VERSION ""

NS_ :

BS_:

BU_: XXX

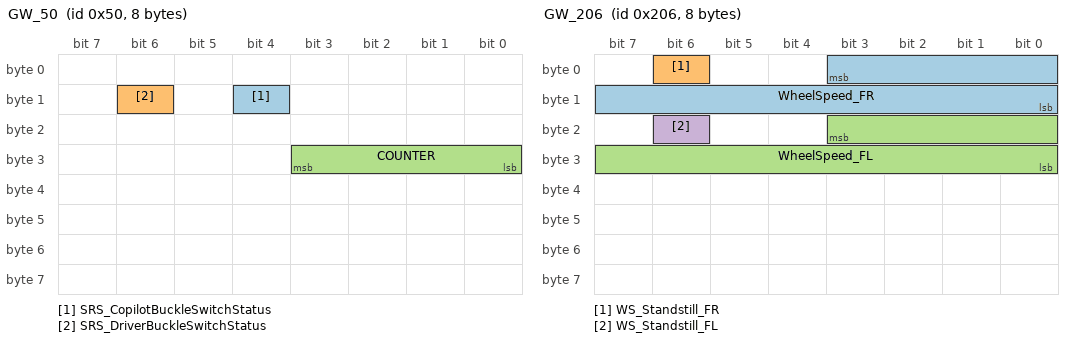
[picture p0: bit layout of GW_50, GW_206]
BO_ 80 GW_50: 8 XXX
 SG_ SRS_CopilotBuckleSwitchStatus : 12|1@0+ (1,0) [0|1] "" XXX
 SG_ SRS_DriverBuckleSwitchStatus : 14|1@0+ (1,0) [0|1] "" XXX
 SG_ COUNTER : 27|4@0+ (1,0) [0|15] "" XXX

BO_ 384 GW_180: 8 XXX
 SG_ SAS_SteeringAngle : 0|16@1- (0.1,1) [-476|476] "deg" XXX
 SG_ SAS_SteeringAngleSpeed : 16|8@0+ (1,0) [0|255] "" XXX
 SG_ COUNTER : 48|4@0+ (1,0) [0|15] "" XXX
 SG_ CHECKSUM : 63|8@0+ (1,0) [0|255] "" XXX

BO_ 391 GW_187: 8 XXX
 SG_ ESP_VehicleSpeed : 39|16@0+ (0.05,0) [0|255] "km/h" XXX
 SG_ COUNTER : 48|4@0+ (1,0) [0|15] "" XXX
 SG_ CHECKSUM : 63|8@0+ (1,0) [0|255] "" XXX

BO_ 424 GW_1A8: 8 XXX
 SG_ GearPosition : 8|4@1+ (1,0) [0|15] "" XXX
 SG_ COUNTER : 48|4@0+ (1,0) [0|15] "" XXX
 SG_ CHECKSUM : 63|8@0+ (1,0) [0|255] "" XXX

BO_ 518 GW_206: 8 XXX
 SG_ WheelSpeed_FR : 3|12@0+ (0.05,0) [0|204.75] "km/h" XXX
 SG_ WS_Standstill_FR : 6|1@0+ (1,0) [0|1] "" XXX
 SG_ WheelSpeed_FL : 19|12@0+ (0.05,0) [0|204.75] "km/h" XXX
 SG_ WS_Standstill_FL : 22|1@0+ (1,0) [0|1] "" XXX

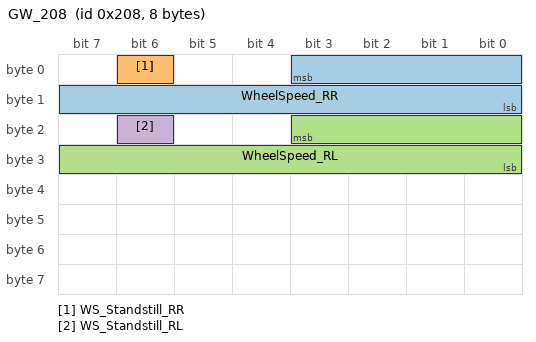
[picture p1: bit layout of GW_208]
BO_ 520 GW_208: 8 XXX
 SG_ WheelSpeed_RR : 3|12@0+ (0.05,0) [0|204.75] "km/h" XXX
 SG_ WS_Standstill_RR : 6|1@0+ (1,0) [0|1] "" XXX
 SG_ WheelSpeed_RL : 19|12@0+ (0.05,0) [0|204.75] "km/h" XXX
 SG_ WS_Standstill_RL : 22|1@0+ (1,0) [0|1] "" XXX

BO_ 618 GW_26A: 8 XXX
 SG_ EMS_AccelSwitch : 0|1@0+ (1,0) [0|1] "" XXX
 SG_ AcceleratorPedalPosition : 47|8@0+ (1,-31) [0|105] "%" XXX

BO_ 631 GW_277: 8 XXX
 SG_ ESP_BrakePedalStatus : 7|1@0+ (1,0) [0|1] "" XXX
 SG_ COUNTER : 48|4@0+ (1,0) [0|15] "" XXX
 SG_ CHECKSUM : 63|8@0+ (1,0) [0|255] "" XXX

BO_ 651 GW_28B: 8 XXX
 SG_ BCM_TurnIndicatorRight : 19|1@0+ (1,0) [0|1] "" XXX
 SG_ BCM_TurnIndicatorLeft : 21|1@0+ (1,0) [0|1] "" XXX
 SG_ BCM_DriverDoorStatus : 23|1@0+ (1,0) [0|1] "" XXX
 SG_ COUNTER : 48|4@0+ (1,0) [0|15] "" XXX
 SG_ CHECKSUM : 63|8@0+ (1,0) [0|255] "" XXX

BO_ 652 GW_28C: 8 XXX
 SG_ CruiseButton : 0|1@0+ (1,0) [0|1] "" XXX
 SG_ CruiseCancel : 2|1@0+ (1,0) [0|1] "" XXX
 SG_ CruiseResume : 4|1@0+ (1,0) [0|1] "" XXX
 SG_ CruiseSet : 6|1@0+ (1,0) [0|1] "" XXX
 SG_ IaccButton : 12|1@0+ (1,0) [0|1] "" XXX
 SG_ COUNTER : 48|4@0+ (1,0) [0|15] "" XXX
 SG_ CHECKSUM : 63|8@0+ (1,0) [0|255] "" XXX

BO_ 600 GW_258: 8 XXX
 SG_ GW258_Type M : 4|4@1+ (1,0) [0|15] "" XXX
 SG_ ESP_BrakePedalDepthLo m0 : 8|8@1+ (1,0) [0|255] "" XXX
 SG_ ESP_BrakePedalDepthHi m0 : 0|1@1+ (1,0) [0|1] "" XXX
 SG_ COUNTER m0 : 48|4@0+ (1,0) [0|15] "" XXX
 SG_ CHECKSUM m0 : 63|8@0+ (1,0) [0|255] "" XXX

CM_ BO_ 384 "zhuanxiangjiao (steering angle, 0|16@0- yanzheng)";
CM_ SG_ 384 SAS_SteeringAngle "zhuanxiangjiao du (steering angle deg)";
CM_ SG_ 384 SAS_SteeringAngleSpeed "zhuanxiangjiao sudu (steering angle rate)";
CM_ BO_ 391 "chesu xinhao (vehicle speed, GW_187)";
CM_ SG_ 391 ESP_VehicleSpeed "chesu km/h (vehicle speed)";
CM_ BO_ 424 "dangwei (gear, 0x1A8 byte1 low nibble: 0x00=N, 0x01-0x07=1-7, 0x09=R, 0x0A=P)";
CM_ SG_ 424 GearPosition "dangwei";
CM_ BO_ 618 "youmen taban (accel pedal GW_26A)";
CM_ SG_ 618 EMS_AccelSwitch "youmen kaiguan byte0 bit0 (accel switch, 0=release 1=pressed)";
CM_ SG_ 618 AcceleratorPedalPosition "youmen kaidu % (accel pedal position, byte5 raw: 31=0%, 136=floor by accanjian.csv)";
CM_ BO_ 631 "shache taban (brake pedal GW_277)";
CM_ BO_ 651 "cheshen kongzhi BCM (body control: doors/turn signals)";
CM_ SG_ 651 BCM_TurnIndicatorRight "you zhuanxiang deng (right turn signal)";
CM_ SG_ 651 BCM_TurnIndicatorLeft "zuo zhuanxiang deng (left turn signal)";
CM_ BO_ 652 "fangxiangpan anjian (steering wheel buttons)";
CM_ SG_ 652 CruiseButton "dingsu";
CM_ SG_ 652 CruiseCancel "Exit_IACC";
CM_ SG_ 652 CruiseResume "RES+ anjian";
CM_ SG_ 652 CruiseSet "SET- anjian";
CM_ SG_ 652 IaccButton "IACC anjian";
CM_ BO_ 600 "shache taban shendu (brake pedal depth GW_258, muxed subframes)";
CM_ SG_ 600 GW258_Type "zizhen leixing (subframe type, byte0 high nibble: 0=pedal frame)";
CM_ SG_ 600 ESP_BrakePedalDepthLo "shache taban shendu di 8 wei (brake pedal depth low byte)";
CM_ SG_ 600 ESP_BrakePedalDepthHi "shache taban shendu di 9 wei (brake pedal depth bit8, value=Lo|Hi<<8, 500=100%)";
VAL_ 80 SRS_CopilotBuckleSwitchStatus 0 "close" 1 "open";
VAL_ 80 SRS_DriverBuckleSwitchStatus 0 "close" 1 "open";
VAL_ 424 GearPosition 0 "N" 1 "D1" 2 "2" 3 "3" 4 "4" 5 "5" 6 "6" 7 "7" 9 "R" 10 "P";
VAL_ 618 EMS_AccelSwitch 0 "release" 1 "pressed";
VAL_ 631 ESP_BrakePedalStatus 0 "release" 1 "pressed";
VAL_ 651 BCM_TurnIndicatorRight 0 "no" 1 "turn_right";
VAL_ 651 BCM_TurnIndicatorLeft 0 "no" 1 "turn_left";
VAL_ 651 BCM_DriverDoorStatus 0 "close" 1 "open";
VAL_ 652 CruiseButton 0 "no" 1 "Press";
VAL_ 652 CruiseCancel 0 "no" 1 "Press";
VAL_ 652 CruiseResume 0 "no" 1 "reset/+";
VAL_ 652 CruiseSet 0 "no" 1 "set-";
VAL_ 652 IaccButton 0 "no" 1 "On_IACC";
VAL_ 600 GW258_Type 0 "PedalFrame";
